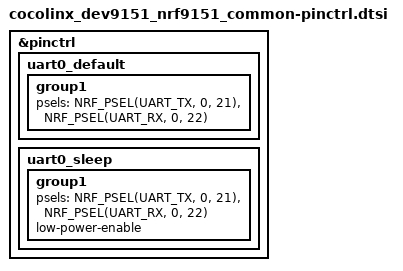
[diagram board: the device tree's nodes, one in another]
/*
 * Copyright (c) 2023 cocolinx
 * SPDX-License-Identifier: Apache-2.0
 */

&pinctrl {
	uart0_default: uart0_default {
		group1 {
			psels = <NRF_PSEL(UART_TX, 0, 21)>,
					<NRF_PSEL(UART_RX, 0, 22)>;
		};
	};
	uart0_sleep: uart0_sleep {
		group1 {
			psels = <NRF_PSEL(UART_TX, 0, 21)>,
					<NRF_PSEL(UART_RX, 0, 22)>;
			low-power-enable;
		};
	};
	// uart2_default: uart2_default {
	// 	group1 {
	// 		psels = <NRF_PSEL(UART_TX, 0, 8)>,
	// 				<NRF_PSEL(UART_RX, 0, 9)>;
	// 	};
	// };
	// uart2_sleep: uart2_sleep {
	// 	group1 {
	// 		psels = <NRF_PSEL(UART_TX, 0, 8)>,
	// 				<NRF_PSEL(UART_RX, 0, 9)>;
	// 		low-power-enable;
	// 	};
	// };

	// pwm0_default: pwm0_default {
	// 	group1 {
	// 		psels = <NRF_PSEL(PWM_OUT0, 0, 30)>;
	// 	};
	// };

	// pwm0_sleep: pwm0_sleep {
	// 	group1 {
	// 		psels = <NRF_PSEL(PWM_OUT0, 0, 30)>;
	// 		low-power-enable;
	// 	};
	// };

	// spi3_default: spi3_default {
	// 	group1 {
	// 		psels = <NRF_PSEL(SPIM_SCK, 0, 29)>,
	// 			<NRF_PSEL(SPIM_MOSI, 0, 31)>,
	// 			<NRF_PSEL(SPIM_MISO, 0, 15)>;
	// 	};
	// };

	// spi3_sleep: spi3_sleep {
	// 	group1 {
	// 		psels = <NRF_PSEL(SPIM_SCK, 0, 29)>,
	// 			<NRF_PSEL(SPIM_MOSI, 0, 31)>,
	// 			<NRF_PSEL(SPIM_MISO, 0, 15)>;
	// 		low-power-enable;
	// 	};
	// };

	// i2c1_default: i2c1_default {
	// 	group1 {
	// 		psels = <NRF_PSEL(TWIM_SDA, 0, 7)>,
	// 			<NRF_PSEL(TWIM_SCL, 0, 6)>;
	// 	};
	// };

	// i2c1_sleep: i2c1_sleep {
	// 	group1 {
	// 		psels = <NRF_PSEL(TWIM_SDA, 0, 7)>,
	// 			<NRF_PSEL(TWIM_SCL, 0, 6)>;
	// 		low-power-enable;
	// 	};
	// };
};
